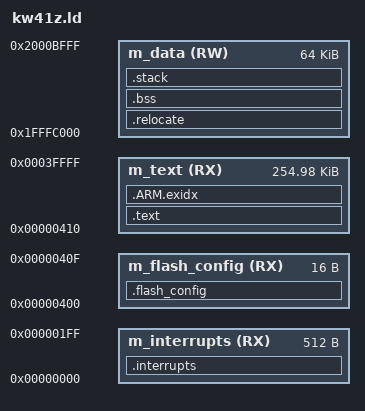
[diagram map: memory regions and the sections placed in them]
/**
 * \file
 *
 * \brief Linker script for running in internal FLASH on the SAMR21G18A
 *
 * Copyright (c) 2015 Atmel Corporation. All rights reserved.
 *
 * \asf_license_start
 *
 * \page License
 *
 * Redistribution and use in source and binary forms, with or without
 * modification, are permitted provided that the following conditions are met:
 *
 * 1. Redistributions of source code must retain the above copyright notice,
 *    this list of conditions and the following disclaimer.
 *
 * 2. Redistributions in binary form must reproduce the above copyright notice,
 *    this list of conditions and the following disclaimer in the documentation
 *    and/or other materials provided with the distribution.
 *
 * 3. The name of Atmel may not be used to endorse or promote products derived
 *    from this software without specific prior written permission.
 *
 * 4. This software may only be redistributed and used in connection with an
 *    Atmel microcontroller product.
 *
 * THIS SOFTWARE IS PROVIDED BY ATMEL "AS IS" AND ANY EXPRESS OR IMPLIED
 * WARRANTIES, INCLUDING, BUT NOT LIMITED TO, THE IMPLIED WARRANTIES OF
 * MERCHANTABILITY, FITNESS FOR A PARTICULAR PURPOSE AND NON-INFRINGEMENT ARE
 * EXPRESSLY AND SPECIFICALLY DISCLAIMED. IN NO EVENT SHALL ATMEL BE LIABLE FOR
 * ANY DIRECT, INDIRECT, INCIDENTAL, SPECIAL, EXEMPLARY, OR CONSEQUENTIAL
 * DAMAGES (INCLUDING, BUT NOT LIMITED TO, PROCUREMENT OF SUBSTITUTE GOODS
 * OR SERVICES; LOSS OF USE, DATA, OR PROFITS; OR BUSINESS INTERRUPTION)
 * HOWEVER CAUSED AND ON ANY THEORY OF LIABILITY, WHETHER IN CONTRACT,
 * STRICT LIABILITY, OR TORT (INCLUDING NEGLIGENCE OR OTHERWISE) ARISING IN
 * ANY WAY OUT OF THE USE OF THIS SOFTWARE, EVEN IF ADVISED OF THE
 * POSSIBILITY OF SUCH DAMAGE.
 *
 * \asf_license_stop
 *
 */

/* Entry Point */
ENTRY(Reset_Handler)

OUTPUT_FORMAT("elf32-littlearm", "elf32-littlearm", "elf32-littlearm")
OUTPUT_ARCH(arm)
SEARCH_DIR(.)

/* Specify the memory areas */
MEMORY
{
  m_interrupts          (RX)  : ORIGIN = 0x00000000, LENGTH = 0x00000200
  m_flash_config        (RX)  : ORIGIN = 0x00000400, LENGTH = 0x00000010
  m_text                (RX)  : ORIGIN = 0x00000410, LENGTH = 0x0003FBF0
  m_data                (RW)  : ORIGIN = 0x1FFFC000, LENGTH = 0x00010000
}

/* The stack size used by the application. NOTE: you need to adjust according to your application. */
STACK_SIZE = DEFINED(STACK_SIZE) ? STACK_SIZE : DEFINED(__stack_size__) ? __stack_size__ : 0x2000;

/* Be identical to FSL_FEATURE_FLASH_PFLASH_BLOCK_SECTOR_SIZE defined in the MKW41Z4_features.h */
FLASH_PAGE_SIZE       = 2048;
FLASH_DATA_PAGES_USED = 8;

/* Section Definitions */
SECTIONS
{
      /* The startup code goes first into internal flash */
    .interrupts :
    {
      __VECTOR_TABLE = .;
      . = ALIGN(4);
      KEEP(*(.isr_vector))     /* Startup code */
      . = ALIGN(4);
    } > m_interrupts

    .flash_config :
    {
      . = ALIGN(4);
      KEEP(*(.FlashConfig))    /* Flash Configuration Field (FCF) */
      . = ALIGN(4);
    } > m_flash_config

    .text :
    {
        . = ALIGN(4);
        _sfixed = .;
        KEEP(*(.vectors .vectors.*))
        *(.text .text.* .gnu.linkonce.t.*)
        *(.glue_7t) *(.glue_7)
        *(.rodata .rodata* .gnu.linkonce.r.*)
        *(.ARM.extab* .gnu.linkonce.armextab.*)

        /* Support C constructors, and C destructors in both user code
           and the C library. This also provides support for C++ code. */
        . = ALIGN(4);
        KEEP(*(.init))
        . = ALIGN(4);
        __preinit_array_start = .;
        KEEP (*(.preinit_array))
        __preinit_array_end = .;

        . = ALIGN(4);
        __init_array_start = .;
        KEEP (*(SORT(.init_array.*)))
        KEEP (*(.init_array))
        __init_array_end = .;

        . = ALIGN(4);
        KEEP (*crtbegin.o(.ctors))
        KEEP (*(EXCLUDE_FILE (*crtend.o) .ctors))
        KEEP (*(SORT(.ctors.*)))
        KEEP (*crtend.o(.ctors))

        . = ALIGN(4);
        KEEP(*(.fini))

        . = ALIGN(4);
        __fini_array_start = .;
        KEEP (*(.fini_array))
        KEEP (*(SORT(.fini_array.*)))
        __fini_array_end = .;

        KEEP (*crtbegin.o(.dtors))
        KEEP (*(EXCLUDE_FILE (*crtend.o) .dtors))
        KEEP (*(SORT(.dtors.*)))
        KEEP (*crtend.o(.dtors))

        . = ALIGN(4);
        _efixed = .;            /* End of text section */
    } > m_text

    /* .ARM.exidx is sorted, so has to go in its own output section.  */
    PROVIDE_HIDDEN (__exidx_start = .);
    .ARM.exidx :
    {
      *(.ARM.exidx* .gnu.linkonce.armexidx.*)
    } > m_text
    PROVIDE_HIDDEN (__exidx_end = .);

    . = ALIGN(4);
    _etext = .;

    .relocate : AT (_etext)
    {
        . = ALIGN(4);
        _srelocate = .;
        *(.ramfunc .ramfunc.*);
        *(.data .data.*);
        . = ALIGN(4);
        _erelocate = .;
    } > m_data

    /* .bss section which is used for uninitialized data */
    .bss (NOLOAD) :
    {
        . = ALIGN(4);
        _sbss = . ;
        _szero = .;
        *(.bss .bss.*)
        *(COMMON)
        . = ALIGN(4);
        _ebss = . ;
        _ezero = .;
    } > m_data

    /* stack section */
    .stack (NOLOAD):
    {
        . = ALIGN(8);
        _sstack = .;
        . = . + STACK_SIZE;
        . = ALIGN(8);
        _estack = .;
    } > m_data

    . = ALIGN(4);
    _end = . ;
    
    __flash_data_end = (ORIGIN(m_text) + LENGTH(m_text));
    __flash_data_start = (__flash_data_end - (FLASH_PAGE_SIZE * FLASH_DATA_PAGES_USED));
    /* Assure that code does not overlap flash data area.*/
    ASSERT((__flash_data_start >= _etext), "Error: Code overlaps flash data area.")
}

